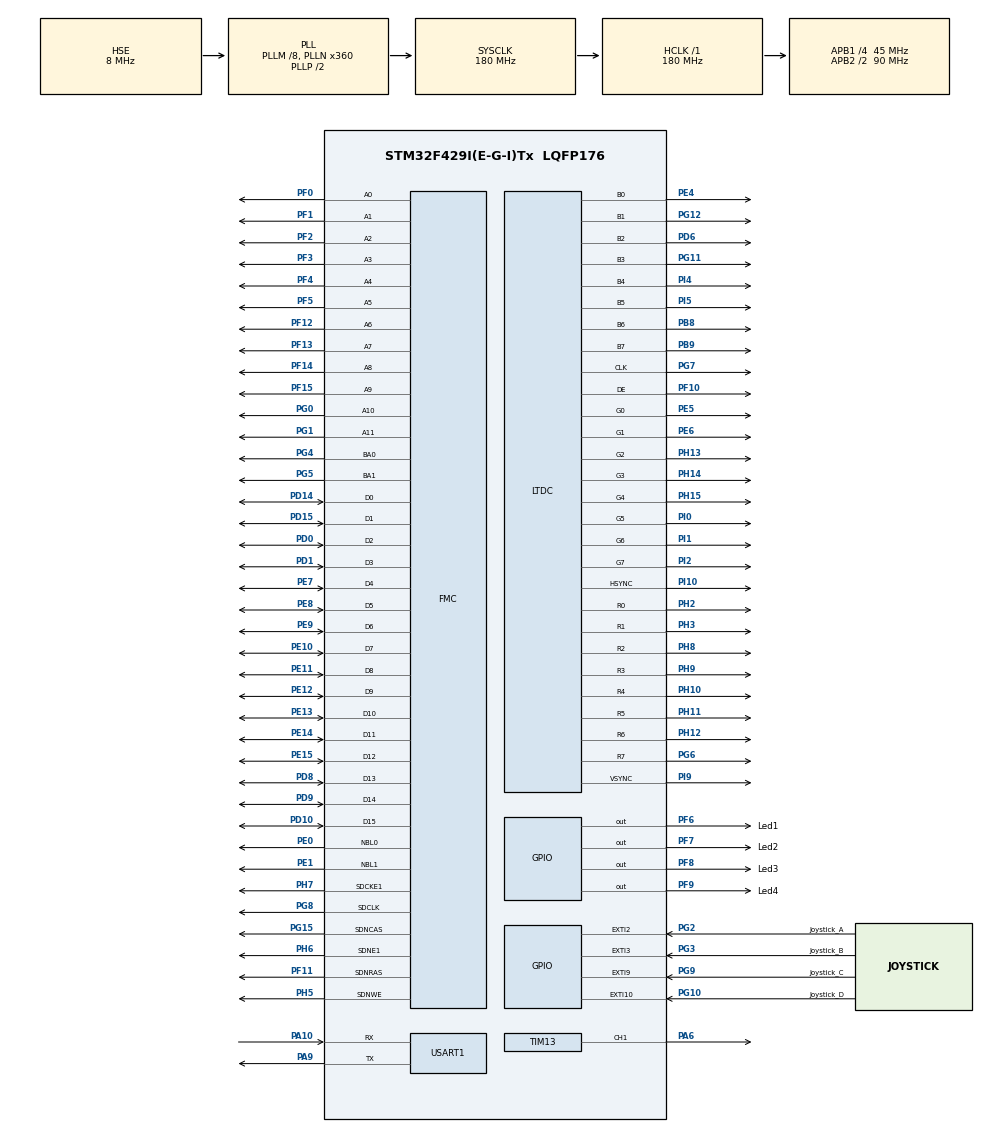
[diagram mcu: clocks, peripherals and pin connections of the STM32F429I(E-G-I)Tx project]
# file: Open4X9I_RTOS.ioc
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DMA2D.AlphaInvertedForeground=DMA2D_REGULAR_ALPHA
DMA2D.AlphaModeForeground=DMA2D_NO_MODIF_ALPHA
DMA2D.ColorMode=DMA2D_OUTPUT_ARGB8888
DMA2D.InputAlphaForeground=0
DMA2D.InputColorModeForeground=DMA2D_INPUT_A4
DMA2D.Mode=DMA2D_M2M_PFC
Dma.Request0=USART1_RX
Dma.Request1=USART1_TX
Dma.USART1_RX.0.Direction=DMA_PERIPH_TO_MEMORY
Dma.USART1_RX.0.FIFOMode=DMA_FIFOMODE_DISABLE
Dma.USART1_RX.0.Instance=DMA2_Stream2
Dma.USART1_RX.0.MemDataAlignment=DMA_MDATAALIGN_BYTE
Dma.USART1_RX.0.MemInc=DMA_MINC_ENABLE
Dma.USART1_RX.0.Mode=DMA_NORMAL
Dma.USART1_RX.0.PeriphDataAlignment=DMA_PDATAALIGN_BYTE
Dma.USART1_RX.0.PeriphInc=DMA_PINC_DISABLE
Dma.USART1_RX.0.Priority=DMA_PRIORITY_MEDIUM
Dma.USART1_TX.1.Direction=DMA_MEMORY_TO_PERIPH
Dma.USART1_TX.1.FIFOMode=DMA_FIFOMODE_DISABLE
Dma.USART1_TX.1.Instance=DMA2_Stream7
Dma.USART1_TX.1.MemDataAlignment=DMA_MDATAALIGN_BYTE
Dma.USART1_TX.1.MemInc=DMA_MINC_ENABLE
Dma.USART1_TX.1.Mode=DMA_NORMAL
Dma.USART1_TX.1.PeriphDataAlignment=DMA_PDATAALIGN_BYTE
Dma.USART1_TX.1.PeriphInc=DMA_PINC_DISABLE
Dma.USART1_TX.1.Priority=DMA_PRIORITY_MEDIUM
FMC.CASLatency2=FMC_SDRAM_CAS_LATENCY_3
FMC.ExitSelfRefreshDelay2=7
FMC.LoadToActiveDelay2=2
FMC.RCDDelay2=2
FMC.RPDelay1=2
FMC.RPDelay2=2
FMC.ReadBurst1=FMC_SDRAM_RBURST_ENABLE
FMC.ReadBurst2=FMC_SDRAM_RBURST_ENABLE
FMC.ReadPipeDelay1=FMC_SDRAM_RPIPE_DELAY_2
FMC.ReadPipeDelay2=FMC_SDRAM_RPIPE_DELAY_2
FMC.RowBitsNumber2=FMC_SDRAM_ROW_BITS_NUM_12
FMC.RowCycleDelay1=6
FMC.RowCycleDelay2=6
FMC.SDClockPeriod1=FMC_SDRAM_CLOCK_PERIOD_2
FMC.SDClockPeriod2=FMC_SDRAM_CLOCK_PERIOD_2
FMC.SelfRefreshTime2=4
FMC.WriteRecoveryTime2=2
FREERTOS.BinarySemaphores01=xRTCSemaphore,Dynamic,NULL;xDMA2DSemaphore,Dynamic,NULL;xBlinkCursorSemaphore,Dynamic,NULL;xLED1Semaphore,Dynamic,NULL;xLED2Semaphore,Dynamic,NULL;xLED3Semaphore,Dynamic,NULL;xLED4Semaphore,Dynamic,NULL;xInputMsgSemaphore,Dynamic,NULL;xCPULoadSemaphore,Dynamic,NULL;xDMA2Stream2Semaphore,Dynamic,NULL;xPS2CharSemaphore,Dynamic,NULL;xTIM6Semaphore,Dynamic,NULL;xTIM7Semaphore,Dynamic,NULL;xDMA2Stream7Semaphore,Dynamic,NULL
FREERTOS.CountingSemaphores01=xCAN_TXSemaphore,3,Dynamic,NULL
FREERTOS.Mutexes01=xCANStructPoint,Dynamic,NULL;xDMA2Stream2,Dynamic,NULL
FREERTOS.Queues01=QueuePrintLCD,16,sizeof LCDPrintTypeDef,NULL,Dynamic,NULL,NULL;QueueCANRecieve,10,sizeof CANRX_TypeDef,NULL,Dynamic,NULL,NULL;QueueCANTransmite,16,sizeof CANTX_TypeDef,NULL,Dynamic,NULL,NULL
FREERTOS.Tasks01=defaultTask,-3,128,StartDefaultTask,Default,NULL,Dynamic,NULL,NULL;LCDPrintCurrent,0,128,vLCDPrintCurrent,As external,NULL,Dynamic,NULL,NULL;PrintKernelLoad,0,128,vPrintKernelLoad,As external,NULL,Dynamic,NULL,NULL;PrintRTC,0,128,vPrintRTC,As external,NULL,Dynamic,NULL,NULL;LED1Blink,0,128,vLED1Blink,As external,NULL,Dynamic,NULL,NULL;LED2Blink,0,128,vLED2Blink,As external,NULL,Dynamic,NULL,NULL;LED3Blink,0,128,vLED3Blink,As external,NULL,Dynamic,NULL,NULL;LED4Blink,0,128,vLED4Blink,As external,NULL,Dynamic,NULL,NULL;CommandMsgDecod,0,128,vCommandMsgDecode,As external,NULL,Dynamic,NULL,NULL;LCDBlinkCursor,-2,128,vLCDBlinkCursor,As external,NULL,Dynamic,NULL,NULL;PS2CharDecode,0,128,vPS2CharDecode,As external,NULL,Dynamic,NULL,NULL
FREERTOS.configTIMER_QUEUE_LENGTH=5
FREERTOS.configTIMER_TASK_STACK_DEPTH=128
FREERTOS.configUSE_COUNTING_SEMAPHORES=1
FREERTOS.configUSE_IDLE_HOOK=1
FREERTOS.configUSE_TIMERS=0
LTDC.ActiveH=272
LTDC.ActiveW=480
LTDC.Alpha_L0=255
LTDC.Alpha_L1=255
LTDC.BlendingFactor1_L0=LTDC_BLENDING_FACTOR1_PAxCA
LTDC.BlendingFactor1_L1=LTDC_BLENDING_FACTOR1_PAxCA
LTDC.BlendingFactor2_L0=LTDC_BLENDING_FACTOR2_PAxCA
LTDC.BlendingFactor2_L1=LTDC_BLENDING_FACTOR2_PAxCA
LTDC.Blue_L0=150
LTDC.Blue_L1=150
LTDC.FBStartAdress_L0=0xD0000000
LTDC.FBStartAdress_L1=0xD00ff000
LTDC.Green_L1=100
LTDC.HBP=2
LTDC.HFP=2
LTDC.HSync=41
LTDC.ImageHeight_L0=240
LTDC.ImageHeight_L1=272
LTDC.ImageWidth_L0=480
LTDC.ImageWidth_L1=480
LTDC.Layers=1
LTDC.PixelFormat_L0=LTDC_PIXEL_FORMAT_ARGB8888
LTDC.Red_L0=100
LTDC.VSync=10
LTDC.WindowX0_L0=0
LTDC.WindowX0_L1=0
LTDC.WindowX1_L0=480
LTDC.WindowX1_L1=480
LTDC.WindowY0_L0=0
LTDC.WindowY0_L1=0
LTDC.WindowY1_L0=240
LTDC.WindowY1_L1=272
Mcu.Family=STM32F4
Mcu.Name=STM32F429I(E-G-I)Tx
Mcu.Package=LQFP176
Mcu.UserConstants=constant,0x10;SDRAM_BASE,0xD0000000;SDRAM_SIZE,0x800000;BLUE,0x000000FF;GREEN,0x0000FF00;RED,0x00FF0000;CYAN,0x0000FFFF;MAGENTA,0x00FF00FF;YELLOW,0x00FFFF00;WHITE,0x00FFFFFF;CURSOR_WIDTH,8;CURSOR_HEIGHT,3;LAYER_0,0;LAYER_1,1;BLACK,0x00000000
NVIC.DMA2D_IRQn=true\:6\:0\:true\:false\:true\:true
NVIC.DMA2_Stream2_IRQn=true\:5\:0\:false\:false\:true\:true
NVIC.DMA2_Stream7_IRQn=true\:5\:0\:false\:false\:true\:true
NVIC.EXTI15_10_IRQn=true\:10\:0\:true\:false\:true\:true
NVIC.EXTI2_IRQn=true\:10\:0\:true\:false\:true\:true
NVIC.EXTI3_IRQn=true\:10\:0\:true\:false\:true\:true
NVIC.EXTI9_5_IRQn=true\:10\:0\:true\:false\:true\:true
NVIC.LTDC_IRQn=true\:5\:0\:false\:false\:true\:true
NVIC.PriorityGroup=NVIC_PRIORITYGROUP_4
NVIC.RTC_WKUP_IRQn=true\:7\:0\:true\:false\:true\:true
NVIC.TIM6_DAC_IRQn=true\:8\:0\:true\:false\:true\:true
NVIC.TIM7_IRQn=true\:8\:0\:true\:false\:true\:true
NVIC.TIM8_TRG_COM_TIM14_IRQn=true\:0\:0\:false\:false\:true\:false
NVIC.TimeBase=TIM8_TRG_COM_TIM14_IRQn
NVIC.TimeBaseIP=TIM14
NVIC.USART1_IRQn=true\:7\:0\:true\:false\:true\:true
PA10.GPIO_Speed=GPIO_SPEED_FREQ_LOW
PA10.Mode=Asynchronous
PA10.Signal=USART1_RX
PA13.Mode=Serial_Wire
PA13.Signal=SYS_JTMS-SWDIO
PA14.Mode=Serial_Wire
PA14.Signal=SYS_JTCK-SWCLK
PA6.Signal=S_TIM13_CH1
PA9.GPIO_Speed=GPIO_SPEED_FREQ_LOW
PA9.Mode=Asynchronous
PA9.Signal=USART1_TX
PB8.GPIO_Mode=GPIO_MODE_AF_PP
PB8.GPIO_PuPd=GPIO_NOPULL
PB8.GPIO_Speed=GPIO_SPEED_FREQ_HIGH
PB8.Mode=RGB888
PB8.Signal=LTDC_B6
PB9.GPIO_Mode=GPIO_MODE_AF_PP
PB9.GPIO_PuPd=GPIO_NOPULL
PB9.GPIO_Speed=GPIO_SPEED_FREQ_HIGH
PB9.Mode=RGB888
PB9.Signal=LTDC_B7
PC14/OSC32_IN.Mode=LSE-External-Oscillator
PC14/OSC32_IN.Signal=RCC_OSC32_IN
PC15/OSC32_OUT.Mode=LSE-External-Oscillator
PC15/OSC32_OUT.Signal=RCC_OSC32_OUT
PD0.Signal=FMC_D2_DA2
PD1.Signal=FMC_D3_DA3
PD10.Signal=FMC_D15_DA15
PD14.Signal=FMC_D0_DA0
PD15.Signal=FMC_D1_DA1
PD6.GPIO_Mode=GPIO_MODE_AF_PP
PD6.GPIO_PuPd=GPIO_NOPULL
PD6.GPIO_Speed=GPIO_SPEED_FREQ_HIGH
PD6.Mode=RGB888
PD6.Signal=LTDC_B2
PD8.Signal=FMC_D13_DA13
PD9.Signal=FMC_D14_DA14
PE0.Signal=FMC_NBL0
PE1.Signal=FMC_NBL1
PE10.Signal=FMC_D7_DA7
PE11.Signal=FMC_D8_DA8
PE12.Signal=FMC_D9_DA9
PE13.Signal=FMC_D10_DA10
PE14.Signal=FMC_D11_DA11
PE15.Signal=FMC_D12_DA12
PE4.GPIO_Mode=GPIO_MODE_AF_PP
PE4.GPIO_PuPd=GPIO_NOPULL
PE4.GPIO_Speed=GPIO_SPEED_FREQ_HIGH
PE4.Mode=RGB888
PE4.Signal=LTDC_B0
PE5.GPIO_Mode=GPIO_MODE_AF_PP
PE5.GPIO_PuPd=GPIO_NOPULL
PE5.GPIO_Speed=GPIO_SPEED_FREQ_HIGH
PE5.Mode=RGB888
PE5.Signal=LTDC_G0
PE6.GPIO_Mode=GPIO_MODE_AF_PP
PE6.GPIO_PuPd=GPIO_NOPULL
PE6.GPIO_Speed=GPIO_SPEED_FREQ_HIGH
PE6.Mode=RGB888
PE6.Signal=LTDC_G1
PE7.Signal=FMC_D4_DA4
PE8.Signal=FMC_D5_DA5
PE9.Signal=FMC_D6_DA6
PF0.Signal=FMC_A0
PF1.Signal=FMC_A1
PF10.GPIO_Mode=GPIO_MODE_AF_PP
PF10.GPIO_PuPd=GPIO_NOPULL
PF10.GPIO_Speed=GPIO_SPEED_FREQ_HIGH
PF10.Mode=RGB888
PF10.Signal=LTDC_DE
PF11.Signal=FMC_SDNRAS
PF12.Signal=FMC_A6
PF13.Signal=FMC_A7
PF14.Signal=FMC_A8
PF15.Signal=FMC_A9
PF2.Signal=FMC_A2
PF3.Signal=FMC_A3
PF4.Signal=FMC_A4
PF5.Signal=FMC_A5
PF6.GPIO_Label=Led1
PF6.Signal=GPIO_Output
PF7.GPIO_Label=Led2
PF7.Signal=GPIO_Output
PF8.GPIO_Label=Led3
PF8.Signal=GPIO_Output
PF9.GPIO_Label=Led4
PF9.Signal=GPIO_Output
PG0.Signal=FMC_A10
PG1.Signal=FMC_A11
PG10.GPIO_Label=Joystick_D
PG10.GPIO_ModeDefaultEXTI=GPIO_MODE_IT_FALLING
PG10.GPIO_PuPd=GPIO_PULLUP
PG10.Signal=GPXTI10
PG11.GPIO_Mode=GPIO_MODE_AF_PP
PG11.GPIO_PuPd=GPIO_NOPULL
PG11.GPIO_Speed=GPIO_SPEED_FREQ_HIGH
PG11.Mode=RGB888
PG11.Signal=LTDC_B3
PG12.GPIO_Mode=GPIO_MODE_AF_PP
PG12.GPIO_PuPd=GPIO_NOPULL
PG12.GPIO_Speed=GPIO_SPEED_FREQ_HIGH
PG12.Mode=RGB888
PG12.Signal=LTDC_B1
PG15.Signal=FMC_SDNCAS
PG2.GPIO_Label=Joystick_A
PG2.GPIO_ModeDefaultEXTI=GPIO_MODE_IT_FALLING
PG2.GPIO_PuPd=GPIO_PULLUP
PG2.Signal=GPXTI2
PG3.GPIO_Label=Joystick_B
PG3.GPIO_ModeDefaultEXTI=GPIO_MODE_IT_FALLING
PG3.GPIO_PuPd=GPIO_PULLUP
PG3.Signal=GPXTI3
PG4.Signal=FMC_A14_BA0
PG5.Signal=FMC_A15_BA1
PG6.GPIO_Mode=GPIO_MODE_AF_PP
PG6.GPIO_PuPd=GPIO_NOPULL
PG6.GPIO_Speed=GPIO_SPEED_FREQ_HIGH
PG6.Mode=RGB888
PG6.Signal=LTDC_R7
PG7.GPIO_Mode=GPIO_MODE_AF_PP
PG7.GPIO_PuPd=GPIO_NOPULL
PG7.GPIO_Speed=GPIO_SPEED_FREQ_HIGH
PG7.Mode=RGB888
PG7.Signal=LTDC_CLK
PG8.Signal=FMC_SDCLK
PG9.GPIO_Label=Joystick_C
PG9.GPIO_ModeDefaultEXTI=GPIO_MODE_IT_FALLING
PG9.GPIO_PuPd=GPIO_PULLUP
PG9.Signal=GPXTI9
PH0/OSC_IN.Mode=HSE-External-Oscillator
PH0/OSC_IN.Signal=RCC_OSC_IN
PH1/OSC_OUT.Mode=HSE-External-Oscillator
PH1/OSC_OUT.Signal=RCC_OSC_OUT
PH10.GPIO_Mode=GPIO_MODE_AF_PP
PH10.GPIO_PuPd=GPIO_NOPULL
PH10.GPIO_Speed=GPIO_SPEED_FREQ_HIGH
PH10.Mode=RGB888
PH10.Signal=LTDC_R4
PH11.GPIO_Mode=GPIO_MODE_AF_PP
PH11.GPIO_PuPd=GPIO_NOPULL
PH11.GPIO_Speed=GPIO_SPEED_FREQ_HIGH
PH11.Mode=RGB888
PH11.Signal=LTDC_R5
PH12.GPIO_Mode=GPIO_MODE_AF_PP
PH12.GPIO_PuPd=GPIO_NOPULL
PH12.GPIO_Speed=GPIO_SPEED_FREQ_HIGH
PH12.Mode=RGB888
PH12.Signal=LTDC_R6
PH13.GPIO_Mode=GPIO_MODE_AF_PP
PH13.GPIO_PuPd=GPIO_NOPULL
PH13.GPIO_Speed=GPIO_SPEED_FREQ_HIGH
PH13.Mode=RGB888
PH13.Signal=LTDC_G2
PH14.GPIO_Mode=GPIO_MODE_AF_PP
PH14.GPIO_PuPd=GPIO_NOPULL
PH14.GPIO_Speed=GPIO_SPEED_FREQ_HIGH
PH14.Mode=RGB888
PH14.Signal=LTDC_G3
PH15.GPIO_Mode=GPIO_MODE_AF_PP
PH15.GPIO_PuPd=GPIO_NOPULL
PH15.GPIO_Speed=GPIO_SPEED_FREQ_HIGH
PH15.Mode=RGB888
PH15.Signal=LTDC_G4
PH2.GPIO_Mode=GPIO_MODE_AF_PP
PH2.GPIO_PuPd=GPIO_NOPULL
PH2.GPIO_Speed=GPIO_SPEED_FREQ_HIGH
PH2.Mode=RGB888
PH2.Signal=LTDC_R0
PH3.GPIO_Mode=GPIO_MODE_AF_PP
PH3.GPIO_PuPd=GPIO_NOPULL
PH3.GPIO_Speed=GPIO_SPEED_FREQ_HIGH
PH3.Mode=RGB888
PH3.Signal=LTDC_R1
PH5.GPIO_Mode=GPIO_MODE_AF_PP
PH5.GPIO_PuPd=GPIO_NOPULL
PH5.GPIO_Speed=GPIO_SPEED_FREQ_VERY_HIGH
PH5.GPIO_Speed_High_Default=GPIO_SPEED_FREQ_VERY_HIGH
PH5.Signal=FMC_SDNWE
PH6.Mode=SdramChipSelect2_2
PH6.Signal=FMC_SDNE1
PH7.Mode=SdramChipSelect2_2
PH7.Signal=FMC_SDCKE1
PH8.GPIO_Mode=GPIO_MODE_AF_PP
PH8.GPIO_PuPd=GPIO_NOPULL
PH8.GPIO_Speed=GPIO_SPEED_FREQ_HIGH
PH8.Mode=RGB888
PH8.Signal=LTDC_R2
PH9.GPIO_Mode=GPIO_MODE_AF_PP
PH9.GPIO_PuPd=GPIO_NOPULL
PH9.GPIO_Speed=GPIO_SPEED_FREQ_HIGH
PH9.Mode=RGB888
PH9.Signal=LTDC_R3
PI0.GPIO_Mode=GPIO_MODE_AF_PP
PI0.GPIO_PuPd=GPIO_NOPULL
PI0.GPIO_Speed=GPIO_SPEED_FREQ_HIGH
PI0.Mode=RGB888
PI0.Signal=LTDC_G5
PI1.GPIO_Mode=GPIO_MODE_AF_PP
PI1.GPIO_PuPd=GPIO_NOPULL
PI1.GPIO_Speed=GPIO_SPEED_FREQ_HIGH
PI1.Mode=RGB888
PI1.Signal=LTDC_G6
PI10.GPIO_Mode=GPIO_MODE_AF_PP
PI10.GPIO_PuPd=GPIO_NOPULL
PI10.GPIO_Speed=GPIO_SPEED_FREQ_HIGH
PI10.Mode=RGB888
PI10.Signal=LTDC_HSYNC
PI2.GPIO_Mode=GPIO_MODE_AF_PP
PI2.GPIO_PuPd=GPIO_NOPULL
PI2.GPIO_Speed=GPIO_SPEED_FREQ_HIGH
PI2.Mode=RGB888
PI2.Signal=LTDC_G7
PI4.GPIO_Mode=GPIO_MODE_AF_PP
PI4.GPIO_PuPd=GPIO_NOPULL
PI4.GPIO_Speed=GPIO_SPEED_FREQ_HIGH
PI4.Mode=RGB888
PI4.Signal=LTDC_B4
PI5.GPIO_Mode=GPIO_MODE_AF_PP
PI5.GPIO_PuPd=GPIO_NOPULL
PI5.GPIO_Speed=GPIO_SPEED_FREQ_HIGH
PI5.Mode=RGB888
PI5.Signal=LTDC_B5
PI9.GPIO_Mode=GPIO_MODE_AF_PP
PI9.GPIO_PuPd=GPIO_NOPULL
PI9.GPIO_Speed=GPIO_SPEED_FREQ_HIGH
PI9.Mode=RGB888
PI9.Signal=LTDC_VSYNC
ProjectManager.HeapSize=0x200
ProjectManager.StackSize=0x400
ProjectManager.TargetToolchain=MDK-ARM V5
RCC.48MHZClocksFreq_Value=45000000
RCC.AHBFreq_Value=180000000
RCC.APB1CLKDivider=RCC_HCLK_DIV4
RCC.APB1Freq_Value=45000000
RCC.APB1TimFreq_Value=90000000
RCC.APB2CLKDivider=RCC_HCLK_DIV2
RCC.APB2Freq_Value=90000000
RCC.APB2TimFreq_Value=180000000
RCC.CortexFreq_Value=180000000
RCC.HCLKFreq_Value=180000000
RCC.HSE_VALUE=8000000
RCC.HSI_VALUE=16000000
RCC.PLLM=8
RCC.PLLN=360
RCC.PLLQ=8
RCC.PLLSAIDivR=RCC_PLLSAIDIVR_16
RCC.PLLSAIN=288
RCC.PLLSourceVirtual=RCC_PLLSOURCE_HSE
RCC.RCC_RTC_Clock_Source=RCC_RTCCLKSOURCE_LSE
RCC.RCC_RTC_Clock_SourceVirtual=RCC_RTCCLKSOURCE_LSE
RCC.SYSCLKFreq_VALUE=180000000
RCC.SYSCLKSource=RCC_SYSCLKSOURCE_PLLCLK
RCC.VCOOutputFreq_Value=360000000
RTC.Date=17
RTC.DayLightSaving=RTC_DAYLIGHTSAVING_NONE
RTC.Hours=12
RTC.Month=RTC_MONTH_AUGUST
RTC.WakeUpClock=RTC_WAKEUPCLOCK_CK_SPRE_16BITS
RTC.WakeUpCounter=0
RTC.WeekDay=RTC_WEEKDAY_FRIDAY
RTC.Year=17
SH.FMC_A0.0=FMC_A0,12b-sda2
SH.FMC_A1.0=FMC_A1,12b-sda2
SH.FMC_A10.0=FMC_A10,12b-sda2
SH.FMC_A11.0=FMC_A11,12b-sda2
SH.FMC_A14_BA0.0=FMC_BA0,FourSdramBanks2
SH.FMC_A15_BA1.0=FMC_BA1,FourSdramBanks2
SH.FMC_A2.0=FMC_A2,12b-sda2
SH.FMC_A3.0=FMC_A3,12b-sda2
SH.FMC_A4.0=FMC_A4,12b-sda2
SH.FMC_A5.0=FMC_A5,12b-sda2
SH.FMC_A6.0=FMC_A6,12b-sda2
SH.FMC_A7.0=FMC_A7,12b-sda2
SH.FMC_A8.0=FMC_A8,12b-sda2
SH.FMC_A9.0=FMC_A9,12b-sda2
SH.FMC_D0_DA0.0=FMC_D0,sd-16b-d2
SH.FMC_D10_DA10.0=FMC_D10,sd-16b-d2
SH.FMC_D11_DA11.0=FMC_D11,sd-16b-d2
SH.FMC_D12_DA12.0=FMC_D12,sd-16b-d2
SH.FMC_D13_DA13.0=FMC_D13,sd-16b-d2
SH.FMC_D14_DA14.0=FMC_D14,sd-16b-d2
SH.FMC_D15_DA15.0=FMC_D15,sd-16b-d2
SH.FMC_D1_DA1.0=FMC_D1,sd-16b-d2
SH.FMC_D2_DA2.0=FMC_D2,sd-16b-d2
SH.FMC_D3_DA3.0=FMC_D3,sd-16b-d2
SH.FMC_D4_DA4.0=FMC_D4,sd-16b-d2
SH.FMC_D5_DA5.0=FMC_D5,sd-16b-d2
SH.FMC_D6_DA6.0=FMC_D6,sd-16b-d2
SH.FMC_D7_DA7.0=FMC_D7,sd-16b-d2
SH.FMC_D8_DA8.0=FMC_D8,sd-16b-d2
SH.FMC_D9_DA9.0=FMC_D9,sd-16b-d2
SH.FMC_NBL0.0=FMC_NBL0,Sd2ByteEnable2
SH.FMC_NBL1.0=FMC_NBL1,Sd2ByteEnable2
SH.FMC_SDCLK.0=FMC_SDCLK,12b-sda2
SH.FMC_SDNCAS.0=FMC_SDNCAS,12b-sda2
SH.FMC_SDNRAS.0=FMC_SDNRAS,12b-sda2
SH.FMC_SDNWE.0=FMC_SDNWE,12b-sda2
SH.S_TIM13_CH1.0=TIM13_CH1,PWM Generation1 CH1
TIM13.Channel=TIM_CHANNEL_1
TIM13.OCMode_PWM=TIM_OCMODE_PWM2
TIM13.OCPolarity_1=TIM_OCPOLARITY_LOW
TIM13.Period=200
TIM13.Prescaler=4499
TIM13.Pulse=70
TIM6.Period=4000
TIM6.Prescaler=44999
TIM7.Period=2000
TIM7.Prescaler=44999
USART1.VirtualMode=VM_ASYNC
VP_CRC_VS_CRC.Mode=CRC_Activate
VP_DMA2D_VS_DMA2D.Mode=DMA2D_Activate
VP_FREERTOS_VS_ENABLE.Mode=Enabled
VP_RTC_VS_RTC_Activate.Mode=RTC_Enabled
VP_RTC_VS_RTC_Calendar.Mode=RTC_Calendar
VP_RTC_VS_RTC_WakeUp_intern.Mode=WakeUp
VP_SYS_VS_tim14.Mode=TIM14
VP_TIM13_VS_ClockSourceINT.Mode=Enable_Timer
VP_TIM6_VS_ClockSourceINT.Mode=Enable_Timer
VP_TIM7_VS_ClockSourceINT.Mode=Enable_Timer
board=Open4X9I_RTOS

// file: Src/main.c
/**
  ******************************************************************************
  * File Name          : main.c
  * Description        : Main program body
  ******************************************************************************
  * This notice applies to any and all portions of this file
  * that are not between comment pairs USER CODE BEGIN and
  * USER CODE END. Other portions of this file, whether
  * inserted by the user or by software development tools
  * are owned by their respective copyright owners.
  *
  * Copyright (c) 2017 STMicroelectronics International N.V.
  * All rights reserved.
  *
  * Redistribution and use in source and binary forms, with or without
  * modification, are permitted, provided that the following conditions are met:
  *
  * 1. Redistribution of source code must retain the above copyright notice,
  *    this list of conditions and the following disclaimer.
  * 2. Redistributions in binary form must reproduce the above copyright notice,
  *    this list of conditions and the following disclaimer in the documentation
  *    and/or other materials provided with the distribution.
  * 3. Neither the name of STMicroelectronics nor the names of other
  *    contributors to this software may be used to endorse or promote products
  *    derived from this software without specific written permission.
  * 4. This software, including modifications and/or derivative works of this
  *    software, must execute solely and exclusively on microcontroller or
  *    microprocessor devices manufactured by or for STMicroelectronics.
  * 5. Redistribution and use of this software other than as permitted under
  *    this license is void and will automatically terminate your rights under
  *    this license.
  *
  * THIS SOFTWARE IS PROVIDED BY STMICROELECTRONICS AND CONTRIBUTORS "AS IS"
  * AND ANY EXPRESS, IMPLIED OR STATUTORY WARRANTIES, INCLUDING, BUT NOT
  * LIMITED TO, THE IMPLIED WARRANTIES OF MERCHANTABILITY, FITNESS FOR A
  * PARTICULAR PURPOSE AND NON-INFRINGEMENT OF THIRD PARTY INTELLECTUAL PROPERTY
  * RIGHTS ARE DISCLAIMED TO THE FULLEST EXTENT PERMITTED BY LAW. IN NO EVENT
  * SHALL STMICROELECTRONICS OR CONTRIBUTORS BE LIABLE FOR ANY DIRECT, INDIRECT,
  * INCIDENTAL, SPECIAL, EXEMPLARY, OR CONSEQUENTIAL DAMAGES (INCLUDING, BUT NOT
  * LIMITED TO, PROCUREMENT OF SUBSTITUTE GOODS OR SERVICES; LOSS OF USE, DATA,
  * OR PROFITS; OR BUSINESS INTERRUPTION) HOWEVER CAUSED AND ON ANY THEORY OF
  * LIABILITY, WHETHER IN CONTRACT, STRICT LIABILITY, OR TORT (INCLUDING
  * NEGLIGENCE OR OTHERWISE) ARISING IN ANY WAY OUT OF THE USE OF THIS SOFTWARE,
  * EVEN IF ADVISED OF THE POSSIBILITY OF SUCH DAMAGE.
  *
  ******************************************************************************
  */
#include "main.h"
#include "stm32f4xx_hal.h"
#include "cmsis_os.h"

/* USER CODE BEGIN Includes */
#include "mytask.h"
#include "LCDdriver.h"
#include "PS2_Keyboard.h"
#include "CAN.h"

#define REFRESH_COUNT           ((uint32_t)1386)   /* SDRAM refresh counter */
#define SDRAM_TIMEOUT           ((uint32_t)0xFFFF)
/* USER CODE END Includes */

CRC_HandleTypeDef hcrc;

DMA2D_HandleTypeDef hdma2d;

LTDC_HandleTypeDef hltdc;

RTC_HandleTypeDef hrtc;

TIM_HandleTypeDef htim6;
TIM_HandleTypeDef htim7;
TIM_HandleTypeDef htim13;

UART_HandleTypeDef huart1;
DMA_HandleTypeDef hdma_usart1_rx;
DMA_HandleTypeDef hdma_usart1_tx;

SDRAM_HandleTypeDef hsdram2;

osThreadId defaultTaskHandle;
osThreadId LCDPrintCurrentHandle;
osThreadId PrintKernelLoadHandle;
osThreadId PrintRTCHandle;
osThreadId LED1BlinkHandle;
osThreadId LED2BlinkHandle;
osThreadId LED3BlinkHandle;
osThreadId LED4BlinkHandle;
osThreadId CommandMsgDecodHandle;
osThreadId LCDBlinkCursorHandle;
osThreadId PS2CharDecodeHandle;
osMessageQId QueuePrintLCDHandle;
osMessageQId QueueCANRecieveHandle;
osMessageQId QueueCANTransmiteHandle;
osMutexId xCANStructPointHandle;
osMutexId xDMA2Stream2Handle;
osSemaphoreId xRTCSemaphoreHandle;
osSemaphoreId xDMA2DSemaphoreHandle;
osSemaphoreId xBlinkCursorSemaphoreHandle;
osSemaphoreId xLED1SemaphoreHandle;
osSemaphoreId xLED2SemaphoreHandle;
osSemaphoreId xLED3SemaphoreHandle;
osSemaphoreId xLED4SemaphoreHandle;
osSemaphoreId xInputMsgSemaphoreHandle;
osSemaphoreId xCPULoadSemaphoreHandle;
osSemaphoreId xDMA2Stream2SemaphoreHandle;
osSemaphoreId xPS2CharSemaphoreHandle;
osSemaphoreId xTIM6SemaphoreHandle;
osSemaphoreId xTIM7SemaphoreHandle;
osSemaphoreId xDMA2Stream7SemaphoreHandle;
osSemaphoreId xCAN_TXSemaphoreHandle;

/* USER CODE BEGIN PV */
/* Private variables ---------------------------------------------------------*/

xQueueHandle xQueueCANTX,xQueueCANRX;
//sThreadId TaskHandle1,TaskHandle2;
/* USER CODE END PV */

void SystemClock_Config(void);
static void MX_GPIO_Init(void);
static void MX_DMA_Init(void);
static void MX_CRC_Init(void);
static void MX_DMA2D_Init(void);
static void MX_FMC_Init(void);
static void MX_LTDC_Init(void);
static void MX_RTC_Init(void);
static void MX_TIM6_Init(void);
static void MX_TIM7_Init(void);
static void MX_TIM13_Init(void);
static void MX_USART1_UART_Init(void);
void StartDefaultTask(void const * argument);
extern void vLCDPrintCurrent(void const * argument);
extern void vPrintKernelLoad(void const * argument);
extern void vPrintRTC(void const * argument);
extern void vLED1Blink(void const * argument);
extern void vLED2Blink(void const * argument);
extern void vLED3Blink(void const * argument);
extern void vLED4Blink(void const * argument);
extern void vCommandMsgDecode(void const * argument);
extern void vLCDBlinkCursor(void const * argument);
extern void vPS2CharDecode(void const * argument);

void HAL_TIM_MspPostInit(TIM_HandleTypeDef *htim);

/* USER CODE BEGIN PFP */
/* Private function prototypes -----------------------------------------------*/

void SDRAM_Initialization_sequence(uint32_t RefreshCount);

/* USER CODE END PFP */

int main(void)
{

  /* MCU Configuration----------------------------------------------------------*/

  /* Reset of all peripherals, Initializes the Flash interface and the Systick. */
  HAL_Init();

  /* Configure the system clock */
  SystemClock_Config();

  /* Initialize all configured peripherals */
  MX_GPIO_Init();
  MX_DMA_Init();
  MX_CRC_Init();
  MX_DMA2D_Init();
  MX_FMC_Init();
  MX_LTDC_Init();
  MX_RTC_Init();
  MX_TIM6_Init();
  MX_TIM7_Init();
  MX_TIM13_Init();
  MX_USART1_UART_Init();

  /* USER CODE BEGIN 2 */
		SDRAM_Initialization_sequence(REFRESH_COUNT);
		HAL_RTCEx_EnableBypassShadow(&hrtc);

  /* USER CODE END 2 */

  /* Create the mutex(es) */
  /* definition and creation of xCANStructPoint */
  osMutexDef(xCANStructPoint);
  xCANStructPointHandle = osMutexCreate(osMutex(xCANStructPoint));

  /* definition and creation of xDMA2Stream2 */
  osMutexDef(xDMA2Stream2);
  xDMA2Stream2Handle = osMutexCreate(osMutex(xDMA2Stream2));

  /* Create the semaphores(s) */
  /* definition and creation of xRTCSemaphore */
  osSemaphoreDef(xRTCSemaphore);
  xRTCSemaphoreHandle = osSemaphoreCreate(osSemaphore(xRTCSemaphore), 1);

  /* definition and creation of xDMA2DSemaphore */
  osSemaphoreDef(xDMA2DSemaphore);
  xDMA2DSemaphoreHandle = osSemaphoreCreate(osSemaphore(xDMA2DSemaphore), 1);

  /* definition and creation of xBlinkCursorSemaphore */
  osSemaphoreDef(xBlinkCursorSemaphore);
  xBlinkCursorSemaphoreHandle = osSemaphoreCreate(osSemaphore(xBlinkCursorSemaphore), 1);

  /* definition and creation of xLED1Semaphore */
  osSemaphoreDef(xLED1Semaphore);
  xLED1SemaphoreHandle = osSemaphoreCreate(osSemaphore(xLED1Semaphore), 1);

  /* definition and creation of xLED2Semaphore */
  osSemaphoreDef(xLED2Semaphore);
  xLED2SemaphoreHandle = osSemaphoreCreate(osSemaphore(xLED2Semaphore), 1);

  /* definition and creation of xLED3Semaphore */
  osSemaphoreDef(xLED3Semaphore);
  xLED3SemaphoreHandle = osSemaphoreCreate(osSemaphore(xLED3Semaphore), 1);

  /* definition and creation of xLED4Semaphore */
  osSemaphoreDef(xLED4Semaphore);
  xLED4SemaphoreHandle = osSemaphoreCreate(osSemaphore(xLED4Semaphore), 1);

  /* definition and creation of xInputMsgSemaphore */
  osSemaphoreDef(xInputMsgSemaphore);
  xInputMsgSemaphoreHandle = osSemaphoreCreate(osSemaphore(xInputMsgSemaphore), 1);

  /* definition and creation of xCPULoadSemaphore */
  osSemaphoreDef(xCPULoadSemaphore);
  xCPULoadSemaphoreHandle = osSemaphoreCreate(osSemaphore(xCPULoadSemaphore), 1);

  /* definition and creation of xDMA2Stream2Semaphore */
  osSemaphoreDef(xDMA2Stream2Semaphore);
  xDMA2Stream2SemaphoreHandle = osSemaphoreCreate(osSemaphore(xDMA2Stream2Semaphore), 1);

  /* definition and creation of xPS2CharSemaphore */
  osSemaphoreDef(xPS2CharSemaphore);
  xPS2CharSemaphoreHandle = osSemaphoreCreate(osSemaphore(xPS2CharSemaphore), 1);

  /* definition and creation of xTIM6Semaphore */
  osSemaphoreDef(xTIM6Semaphore);
  xTIM6SemaphoreHandle = osSemaphoreCreate(osSemaphore(xTIM6Semaphore), 1);

  /* definition and creation of xTIM7Semaphore */
  osSemaphoreDef(xTIM7Semaphore);
  xTIM7SemaphoreHandle = osSemaphoreCreate(osSemaphore(xTIM7Semaphore), 1);

  /* definition and creation of xDMA2Stream7Semaphore */
  osSemaphoreDef(xDMA2Stream7Semaphore);
  xDMA2Stream7SemaphoreHandle = osSemaphoreCreate(osSemaphore(xDMA2Stream7Semaphore), 1);

  /* definition and creation of xCAN_TXSemaphore */
  osSemaphoreDef(xCAN_TXSemaphore);
  xCAN_TXSemaphoreHandle = osSemaphoreCreate(osSemaphore(xCAN_TXSemaphore), 1);

  /* Create the thread(s) */
  /* definition and creation of defaultTask */
  osThreadDef(defaultTask, StartDefaultTask, osPriorityIdle, 0, 128);
  defaultTaskHandle = osThreadCreate(osThread(defaultTask), NULL);

  /* definition and creation of LCDPrintCurrent */
  osThreadDef(LCDPrintCurrent, vLCDPrintCurrent, osPriorityNormal, 0, 128);
  LCDPrintCurrentHandle = osThreadCreate(osThread(LCDPrintCurrent), NULL);

  /* definition and creation of PrintKernelLoad */
  osThreadDef(PrintKernelLoad, vPrintKernelLoad, osPriorityNormal, 0, 128);
  PrintKernelLoadHandle = osThreadCreate(osThread(PrintKernelLoad), NULL);

  /* definition and creation of PrintRTC */
  osThreadDef(PrintRTC, vPrintRTC, osPriorityNormal, 0, 128);
  PrintRTCHandle = osThreadCreate(osThread(PrintRTC), NULL);

  /* definition and creation of LED1Blink */
  osThreadDef(LED1Blink, vLED1Blink, osPriorityNormal, 0, 128);
  LED1BlinkHandle = osThreadCreate(osThread(LED1Blink), NULL);

  /* definition and creation of LED2Blink */
  osThreadDef(LED2Blink, vLED2Blink, osPriorityNormal, 0, 128);
  LED2BlinkHandle = osThreadCreate(osThread(LED2Blink), NULL);

  /* definition and creation of LED3Blink */
  osThreadDef(LED3Blink, vLED3Blink, osPriorityNormal, 0, 128);
  LED3BlinkHandle = osThreadCreate(osThread(LED3Blink), NULL);

  /* definition and creation of LED4Blink */
  osThreadDef(LED4Blink, vLED4Blink, osPriorityNormal, 0, 128);
  LED4BlinkHandle = osThreadCreate(osThread(LED4Blink), NULL);

  /* definition and creation of CommandMsgDecod */
  osThreadDef(CommandMsgDecod, vCommandMsgDecode, osPriorityNormal, 0, 128);
  CommandMsgDecodHandle = osThreadCreate(osThread(CommandMsgDecod), NULL);

  /* definition and creation of LCDBlinkCursor */
  osThreadDef(LCDBlinkCursor, vLCDBlinkCursor, osPriorityLow, 0, 128);
  LCDBlinkCursorHandle = osThreadCreate(osThread(LCDBlinkCursor), NULL);

  /* definition and creation of PS2CharDecode */
  osThreadDef(PS2CharDecode, vPS2CharDecode, osPriorityNormal, 0, 128);
  PS2CharDecodeHandle = osThreadCreate(osThread(PS2CharDecode), NULL);

  /* USER CODE BEGIN RTOS_THREADS */
  /* add threads, ... */

	osThreadSuspend (LCDPrintCurrentHandle);
	osThreadSuspend (PrintKernelLoadHandle);
	osThreadSuspend (PrintRTCHandle);
	osThreadSuspend (LED1BlinkHandle);
	osThreadSuspend (LED2BlinkHandle);
	osThreadSuspend (LED3BlinkHandle);
	osThreadSuspend (LED4BlinkHandle);
	osThreadSuspend(CommandMsgDecodHandle);
	osThreadSuspend(LCDBlinkCursorHandle);
	osThreadSuspend(PS2CharDecodeHandle);

	osSemaphoreWait(xLED1SemaphoreHandle,osWaitForever);
	osSemaphoreWait(xLED2SemaphoreHandle,osWaitForever);
	osSemaphoreWait(xLED3SemaphoreHandle,osWaitForever);
	osSemaphoreWait(xLED4SemaphoreHandle,osWaitForever);
	osSemaphoreWait(xDMA2Stream2SemaphoreHandle,osWaitForever);
	osSemaphoreWait(xInputMsgSemaphoreHandle,osWaitForever);
	osSemaphoreWait(xPS2CharSemaphoreHandle,osWaitForever);
	osSemaphoreWait(xTIM6SemaphoreHandle,osWaitForever);
	osSemaphoreWait(xTIM7SemaphoreHandle,osWaitForever);

	HAL_TIM_PWM_Start(&htim13, TIM_CHANNEL_1);

	TIM6->DIER |= TIM_DIER_UIE; 				//разрешаем прерывание от таймера обновления структуры GUI_PID_STATE
	TIM6->EGR = TIM_EGR_UG;							//генерируем "update event". ARR и PSC грузятся из предварительного в теневой регистр.
	TIM6->SR&=~TIM_SR_UIF; 							//Сбрасываем флаг UIF
	NVIC_ClearPendingIRQ(TIM6_DAC_IRQn);

	TIM7->DIER |= TIM_DIER_UIE; 				//разрешаем прерывание от таймера обновления структуры GUI_PID_STATE
	TIM7->EGR = TIM_EGR_UG;							//генерируем "update event". ARR и PSC грузятся из предварительного в теневой регистр.
	TIM7->SR&=~TIM_SR_UIF; 							//Сбрасываем флаг UIF
	NVIC_ClearPendingIRQ(TIM7_IRQn);

  /* USER CODE END RTOS_THREADS */

  /* Create the queue(s) */
  /* definition and creation of QueuePrintLCD */
  osMessageQDef(QueuePrintLCD, 16, sizeof(LCDPrintTypeDef));
  QueuePrintLCDHandle = osMessageCreate(osMessageQ(QueuePrintLCD), NULL);

  /* definition and creation of QueueCANRecieve */
  //osMessageQDef(QueueCANRecieve, 10, sizeof(CANRX_TypeDef));
 // QueueCANRecieveHandle = osMessageCreate(osMessageQ(QueueCANRecieve), NULL);

  /* definition and creation of QueueCANTransmite */
 // osMessageQDef(QueueCANTransmite, 16, sizeof(CANTX_TypeDef));
 // QueueCANTransmiteHandle = osMessageCreate(osMessageQ(QueueCANTransmite), NULL);

  /* USER CODE BEGIN RTOS_QUEUES */
  /* add queues, ... */

		xQueueCANTX=xQueueCreate(4,sizeof(CANTX_TypeDef));
		xQueueCANRX=xQueueCreate(16,sizeof(CANRX_TypeDef));
  /* USER CODE END RTOS_QUEUES */

  /* Start scheduler */
  osKernelStart();

  /* We should never get here as control is now taken by the scheduler */

  /* Infinite loop */
  while (1)
  {

	}

}

/** System Clock Configuration
*/
void SystemClock_Config(void)
{

  RCC_OscInitTypeDef RCC_OscInitStruct;
  RCC_ClkInitTypeDef RCC_ClkInitStruct;
  RCC_PeriphCLKInitTypeDef PeriphClkInitStruct;

    /**Configure the main internal regulator output voltage
    */
  __HAL_RCC_PWR_CLK_ENABLE();

  __HAL_PWR_VOLTAGESCALING_CONFIG(PWR_REGULATOR_VOLTAGE_SCALE1);

    /**Initializes the CPU, AHB and APB busses clocks
    */
  RCC_OscInitStruct.OscillatorType = RCC_OSCILLATORTYPE_HSE|RCC_OSCILLATORTYPE_LSE;
  RCC_OscInitStruct.HSEState = RCC_HSE_ON;
  RCC_OscInitStruct.LSEState = RCC_LSE_ON;
  RCC_OscInitStruct.PLL.PLLState = RCC_PLL_ON;
  RCC_OscInitStruct.PLL.PLLSource = RCC_PLLSOURCE_HSE;
  RCC_OscInitStruct.PLL.PLLM = 8;
  RCC_OscInitStruct.PLL.PLLN = 360;
  RCC_OscInitStruct.PLL.PLLP = RCC_PLLP_DIV2;
  RCC_OscInitStruct.PLL.PLLQ = 8;
  if (HAL_RCC_OscConfig(&RCC_OscInitStruct) != HAL_OK)
  {
    _Error_Handler(__FILE__, __LINE__);
  }

    /**Activate the Over-Drive mode
    */
  if (HAL_PWREx_EnableOverDrive() != HAL_OK)
  {
    _Error_Handler(__FILE__, __LINE__);
  }

    /**Initializes the CPU, AHB and APB busses clocks
    */
  RCC_ClkInitStruct.ClockType = RCC_CLOCKTYPE_HCLK|RCC_CLOCKTYPE_SYSCLK
                              |RCC_CLOCKTYPE_PCLK1|RCC_CLOCKTYPE_PCLK2;
  RCC_ClkInitStruct.SYSCLKSource = RCC_SYSCLKSOURCE_PLLCLK;
  RCC_ClkInitStruct.AHBCLKDivider = RCC_SYSCLK_DIV1;
  RCC_ClkInitStruct.APB1CLKDivider = RCC_HCLK_DIV4;
  RCC_ClkInitStruct.APB2CLKDivider = RCC_HCLK_DIV2;

  if (HAL_RCC_ClockConfig(&RCC_ClkInitStruct, FLASH_LATENCY_5) != HAL_OK)
  {
    _Error_Handler(__FILE__, __LINE__);
  }

  PeriphClkInitStruct.PeriphClockSelection = RCC_PERIPHCLK_LTDC|RCC_PERIPHCLK_RTC;
  PeriphClkInitStruct.PLLSAI.PLLSAIN = 288;
  PeriphClkInitStruct.PLLSAI.PLLSAIR = 2;
  PeriphClkInitStruct.PLLSAIDivR = RCC_PLLSAIDIVR_16;
  PeriphClkInitStruct.RTCClockSelection = RCC_RTCCLKSOURCE_LSE;
  if (HAL_RCCEx_PeriphCLKConfig(&PeriphClkInitStruct) != HAL_OK)
  {
    _Error_Handler(__FILE__, __LINE__);
  }

    /**Configure the Systick interrupt time
    */
  HAL_SYSTICK_Config(HAL_RCC_GetHCLKFreq()/1000);

    /**Configure the Systick
    */
  HAL_SYSTICK_CLKSourceConfig(SYSTICK_CLKSOURCE_HCLK);

  /* SysTick_IRQn interrupt configuration */
  HAL_NVIC_SetPriority(SysTick_IRQn, 15, 0);
}

/* CRC init function */
static void MX_CRC_Init(void)
{

  hcrc.Instance = CRC;
  if (HAL_CRC_Init(&hcrc) != HAL_OK)
  {
    _Error_Handler(__FILE__, __LINE__);
  }

}

/* DMA2D init function */
static void MX_DMA2D_Init(void)
{

  hdma2d.Instance = DMA2D;
  hdma2d.Init.Mode = DMA2D_M2M_PFC;
  hdma2d.Init.ColorMode = DMA2D_OUTPUT_ARGB8888;
  hdma2d.Init.OutputOffset = 0;
  hdma2d.LayerCfg[1].InputOffset = 0;
  hdma2d.LayerCfg[1].InputColorMode = DMA2D_INPUT_A4;
  hdma2d.LayerCfg[1].AlphaMode = DMA2D_NO_MODIF_ALPHA;
  hdma2d.LayerCfg[1].InputAlpha = 0;
  if (HAL_DMA2D_Init(&hdma2d) != HAL_OK)
  {
    _Error_Handler(__FILE__, __LINE__);
  }

  if (HAL_DMA2D_ConfigLayer(&hdma2d, 1) != HAL_OK)
  {
    _Error_Handler(__FILE__, __LINE__);
  }

}

/* LTDC init function */
static void MX_LTDC_Init(void)
{

  LTDC_LayerCfgTypeDef pLayerCfg;
  LTDC_LayerCfgTypeDef pLayerCfg1;

  hltdc.Instance = LTDC;
  hltdc.Init.HSPolarity = LTDC_HSPOLARITY_AL;
  hltdc.Init.VSPolarity = LTDC_VSPOLARITY_AL;
  hltdc.Init.DEPolarity = LTDC_DEPOLARITY_AL;
  hltdc.Init.PCPolarity = LTDC_PCPOLARITY_IPC;
  hltdc.Init.HorizontalSync = 40;
  hltdc.Init.VerticalSync = 9;
  hltdc.Init.AccumulatedHBP = 42;
  hltdc.Init.AccumulatedVBP = 11;
  hltdc.Init.AccumulatedActiveW = 522;
  hltdc.Init.AccumulatedActiveH = 283;
  hltdc.Init.TotalWidth = 524;
  hltdc.Init.TotalHeigh = 285;
  hltdc.Init.Backcolor.Blue = 0;
  hltdc.Init.Backcolor.Green = 0;
  hltdc.Init.Backcolor.Red = 0;
  if (HAL_LTDC_Init(&hltdc) != HAL_OK)
  {
    _Error_Handler(__FILE__, __LINE__);
  }

  pLayerCfg.WindowX0 = 0;
  pLayerCfg.WindowX1 = 480;
  pLayerCfg.WindowY0 = 0;
  pLayerCfg.WindowY1 = 240;
  pLayerCfg.PixelFormat = LTDC_PIXEL_FORMAT_ARGB8888;
  pLayerCfg.Alpha = 255;
  pLayerCfg.Alpha0 = 0;
  pLayerCfg.BlendingFactor1 = LTDC_BLENDING_FACTOR1_PAxCA;
  pLayerCfg.BlendingFactor2 = LTDC_BLENDING_FACTOR2_PAxCA;
  pLayerCfg.FBStartAdress = 0xD0000000;
  pLayerCfg.ImageWidth = 480;
  pLayerCfg.ImageHeight = 240;
  pLayerCfg.Backcolor.Blue = 150;
  pLayerCfg.Backcolor.Green = 0;
  pLayerCfg.Backcolor.Red = 100;
  if (HAL_LTDC_ConfigLayer(&hltdc, &pLayerCfg, 0) != HAL_OK)
  {
    _Error_Handler(__FILE__, __LINE__);
  }

  pLayerCfg1.WindowX0 = 0;
  pLayerCfg1.WindowX1 = 480;
  pLayerCfg1.WindowY0 = 0;
  pLayerCfg1.WindowY1 = 272;
  pLayerCfg1.PixelFormat = LTDC_PIXEL_FORMAT_ARGB8888;
  pLayerCfg1.Alpha = 255;
  pLayerCfg1.Alpha0 = 0;
  pLayerCfg1.BlendingFactor1 = LTDC_BLENDING_FACTOR1_PAxCA;
  pLayerCfg1.BlendingFactor2 = LTDC_BLENDING_FACTOR2_PAxCA;
  pLayerCfg1.FBStartAdress = 0xD00ff000;
  pLayerCfg1.ImageWidth = 480;
  pLayerCfg1.ImageHeight = 272;
  pLayerCfg1.Backcolor.Blue = 150;
  pLayerCfg1.Backcolor.Green = 100;
  pLayerCfg1.Backcolor.Red = 0;
  if (HAL_LTDC_ConfigLayer(&hltdc, &pLayerCfg1, 1) != HAL_OK)
  {
    _Error_Handler(__FILE__, __LINE__);
  }

}

/* RTC init function */
static void MX_RTC_Init(void)
{

  RTC_TimeTypeDef sTime;
  RTC_DateTypeDef sDate;

    /**Initialize RTC Only
    */
  hrtc.Instance = RTC;
  hrtc.Init.HourFormat = RTC_HOURFORMAT_24;
  hrtc.Init.AsynchPrediv = 127;
  hrtc.Init.SynchPrediv = 255;
  hrtc.Init.OutPut = RTC_OUTPUT_DISABLE;
  hrtc.Init.OutPutPolarity = RTC_OUTPUT_POLARITY_HIGH;
  hrtc.Init.OutPutType = RTC_OUTPUT_TYPE_OPENDRAIN;
  if (HAL_RTC_Init(&hrtc) != HAL_OK)
  {
    _Error_Handler(__FILE__, __LINE__);
  }

    /**Initialize RTC and set the Time and Date
    */
  if(HAL_RTCEx_BKUPRead(&hrtc, RTC_BKP_DR0) != 0x32F2){
  sTime.Hours = 0x12;
  sTime.Minutes = 0x0;
  sTime.Seconds = 0x0;
  sTime.DayLightSaving = RTC_DAYLIGHTSAVING_NONE;
  sTime.StoreOperation = RTC_STOREOPERATION_RESET;
  if (HAL_RTC_SetTime(&hrtc, &sTime, RTC_FORMAT_BCD) != HAL_OK)
  {
    _Error_Handler(__FILE__, __LINE__);
  }

  sDate.WeekDay = RTC_WEEKDAY_FRIDAY;
  sDate.Month = RTC_MONTH_AUGUST;
  sDate.Date = 0x17;
  sDate.Year = 0x17;

  if (HAL_RTC_SetDate(&hrtc, &sDate, RTC_FORMAT_BCD) != HAL_OK)
  {
    _Error_Handler(__FILE__, __LINE__);
  }

    HAL_RTCEx_BKUPWrite(&hrtc,RTC_BKP_DR0,0x32F2);
  }
    /**Enable the WakeUp
    */
  __HAL_RTC_WAKEUPTIMER_CLEAR_FLAG(&hrtc, RTC_FLAG_WUTF);

  if (HAL_RTCEx_SetWakeUpTimer_IT(&hrtc, 0, RTC_WAKEUPCLOCK_CK_SPRE_16BITS) != HAL_OK)
  {
    _Error_Handler(__FILE__, __LINE__);
  }

}

/* TIM6 init function */
static void MX_TIM6_Init(void)
{

  TIM_MasterConfigTypeDef sMasterConfig;

  htim6.Instance = TIM6;
  htim6.Init.Prescaler = 44999;
  htim6.Init.CounterMode = TIM_COUNTERMODE_UP;
  htim6.Init.Period = 4000;
  if (HAL_TIM_Base_Init(&htim6) != HAL_OK)
  {
    _Error_Handler(__FILE__, __LINE__);
  }

  sMasterConfig.MasterOutputTrigger = TIM_TRGO_RESET;
  sMasterConfig.MasterSlaveMode = TIM_MASTERSLAVEMODE_DISABLE;
  if (HAL_TIMEx_MasterConfigSynchronization(&htim6, &sMasterConfig) != HAL_OK)
  {
    _Error_Handler(__FILE__, __LINE__);
  }

}

/* TIM7 init function */
static void MX_TIM7_Init(void)
{

  TIM_MasterConfigTypeDef sMasterConfig;

  htim7.Instance = TIM7;
  htim7.Init.Prescaler = 44999;
  htim7.Init.CounterMode = TIM_COUNTERMODE_UP;
  htim7.Init.Period = 2000;
  if (HAL_TIM_Base_Init(&htim7) != HAL_OK)
  {
    _Error_Handler(__FILE__, __LINE__);
  }

  sMasterConfig.MasterOutputTrigger = TIM_TRGO_RESET;
  sMasterConfig.MasterSlaveMode = TIM_MASTERSLAVEMODE_DISABLE;
  if (HAL_TIMEx_MasterConfigSynchronization(&htim7, &sMasterConfig) != HAL_OK)
  {
    _Error_Handler(__FILE__, __LINE__);
  }

}

/* TIM13 init function */
static void MX_TIM13_Init(void)
{

  TIM_OC_InitTypeDef sConfigOC;

  htim13.Instance = TIM13;
  htim13.Init.Prescaler = 4499;
  htim13.Init.CounterMode = TIM_COUNTERMODE_UP;
  htim13.Init.Period = 200;
  htim13.Init.ClockDivision = TIM_CLOCKDIVISION_DIV1;
  if (HAL_TIM_Base_Init(&htim13) != HAL_OK)
  {
    _Error_Handler(__FILE__, __LINE__);
  }

  if (HAL_TIM_PWM_Init(&htim13) != HAL_OK)
  {
    _Error_Handler(__FILE__, __LINE__);
  }

  sConfigOC.OCMode = TIM_OCMODE_PWM2;
  sConfigOC.Pulse = 70;
  sConfigOC.OCPolarity = TIM_OCPOLARITY_LOW;
  sConfigOC.OCFastMode = TIM_OCFAST_DISABLE;
  if (HAL_TIM_PWM_ConfigChannel(&htim13, &sConfigOC, TIM_CHANNEL_1) != HAL_OK)
  {
    _Error_Handler(__FILE__, __LINE__);
  }

  HAL_TIM_MspPostInit(&htim13);

}

/* USART1 init function */
static void MX_USART1_UART_Init(void)
{

  huart1.Instance = USART1;
  huart1.Init.BaudRate = 115200;
  huart1.Init.WordLength = UART_WORDLENGTH_8B;
  huart1.Init.StopBits = UART_STOPBITS_1;
  huart1.Init.Parity = UART_PARITY_NONE;
  huart1.Init.Mode = UART_MODE_TX_RX;
  huart1.Init.HwFlowCtl = UART_HWCONTROL_NONE;
  huart1.Init.OverSampling = UART_OVERSAMPLING_16;
  if (HAL_UART_Init(&huart1) != HAL_OK)
  {
    _Error_Handler(__FILE__, __LINE__);
  }

}

static void MX_DMA_Init(void)
{
  /* DMA controller clock enable */
  __HAL_RCC_DMA2_CLK_ENABLE();

  /* DMA interrupt init */
  /* DMA2_Stream2_IRQn interrupt configuration */
  HAL_NVIC_SetPriority(DMA2_Stream2_IRQn, 5, 0);
  HAL_NVIC_EnableIRQ(DMA2_Stream2_IRQn);
  /* DMA2_Stream7_IRQn interrupt configuration */
  HAL_NVIC_SetPriority(DMA2_Stream7_IRQn, 5, 0);
  HAL_NVIC_EnableIRQ(DMA2_Stream7_IRQn);

}
/* FMC initialization function */
static void MX_FMC_Init(void)
{
  FMC_SDRAM_TimingTypeDef SdramTiming;

  /** Perform the SDRAM2 memory initialization sequence
  */
  hsdram2.Instance = FMC_SDRAM_DEVICE;
  /* hsdram2.Init */
  hsdram2.Init.SDBank = FMC_SDRAM_BANK2;
  hsdram2.Init.ColumnBitsNumber = FMC_SDRAM_COLUMN_BITS_NUM_8;
  hsdram2.Init.RowBitsNumber = FMC_SDRAM_ROW_BITS_NUM_12;
  hsdram2.Init.MemoryDataWidth = FMC_SDRAM_MEM_BUS_WIDTH_16;
  hsdram2.Init.InternalBankNumber = FMC_SDRAM_INTERN_BANKS_NUM_4;
  hsdram2.Init.CASLatency = FMC_SDRAM_CAS_LATENCY_3;
  hsdram2.Init.WriteProtection = FMC_SDRAM_WRITE_PROTECTION_DISABLE;
  hsdram2.Init.SDClockPeriod = FMC_SDRAM_CLOCK_PERIOD_2;
  hsdram2.Init.ReadBurst = FMC_SDRAM_RBURST_ENABLE;
  hsdram2.Init.ReadPipeDelay = FMC_SDRAM_RPIPE_DELAY_2;
  /* SdramTiming */
  SdramTiming.LoadToActiveDelay = 2;
  SdramTiming.ExitSelfRefreshDelay = 7;
  SdramTiming.SelfRefreshTime = 4;
  SdramTiming.RowCycleDelay = 6;
  SdramTiming.WriteRecoveryTime = 2;
  SdramTiming.RPDelay = 2;
  SdramTiming.RCDDelay = 2;

  if (HAL_SDRAM_Init(&hsdram2, &SdramTiming) != HAL_OK)
  {
    _Error_Handler(__FILE__, __LINE__);
  }

}

/** Configure pins as
        * Analog
        * Input
        * Output
        * EVENT_OUT
        * EXTI
*/
static void MX_GPIO_Init(void)
{

  GPIO_InitTypeDef GPIO_InitStruct;

  /* GPIO Ports Clock Enable */
  __HAL_RCC_GPIOE_CLK_ENABLE();
  __HAL_RCC_GPIOC_CLK_ENABLE();
  __HAL_RCC_GPIOI_CLK_ENABLE();
  __HAL_RCC_GPIOF_CLK_ENABLE();
  __HAL_RCC_GPIOH_CLK_ENABLE();
  __HAL_RCC_GPIOA_CLK_ENABLE();
  __HAL_RCC_GPIOG_CLK_ENABLE();
  __HAL_RCC_GPIOD_CLK_ENABLE();
  __HAL_RCC_GPIOB_CLK_ENABLE();

  /*Configure GPIO pin Output Level */
  HAL_GPIO_WritePin(GPIOF, Led1_Pin|Led2_Pin|Led3_Pin|Led4_Pin, GPIO_PIN_RESET);

  /*Configure GPIO pins : Led1_Pin Led2_Pin Led3_Pin Led4_Pin */
  GPIO_InitStruct.Pin = Led1_Pin|Led2_Pin|Led3_Pin|Led4_Pin;
  GPIO_InitStruct.Mode = GPIO_MODE_OUTPUT_PP;
  GPIO_InitStruct.Pull = GPIO_NOPULL;
  GPIO_InitStruct.Speed = GPIO_SPEED_FREQ_LOW;
  HAL_GPIO_Init(GPIOF, &GPIO_InitStruct);

  /*Configure GPIO pins : Joystick_A_Pin Joystick_B_Pin Joystick_C_Pin Joystick_D_Pin */
  GPIO_InitStruct.Pin = Joystick_A_Pin|Joystick_B_Pin|Joystick_C_Pin|Joystick_D_Pin;
  GPIO_InitStruct.Mode = GPIO_MODE_IT_FALLING;
  GPIO_InitStruct.Pull = GPIO_PULLUP;
  HAL_GPIO_Init(GPIOG, &GPIO_InitStruct);

  /* EXTI interrupt init*/
  HAL_NVIC_SetPriority(EXTI2_IRQn, 10, 0);
  HAL_NVIC_EnableIRQ(EXTI2_IRQn);

  HAL_NVIC_SetPriority(EXTI3_IRQn, 10, 0);
  HAL_NVIC_EnableIRQ(EXTI3_IRQn);

  HAL_NVIC_SetPriority(EXTI9_5_IRQn, 10, 0);
  HAL_NVIC_EnableIRQ(EXTI9_5_IRQn);

  HAL_NVIC_SetPriority(EXTI15_10_IRQn, 10, 0);
  HAL_NVIC_EnableIRQ(EXTI15_10_IRQn);

}

/* USER CODE BEGIN 4 */

void SDRAM_Initialization_sequence(uint32_t RefreshCount)
{
	uint32_t tmp;

#define SDRAM_MODEREG_BURST_LENGTH_1             ((uint16_t)0x0000)
	#define SDRAM_MODEREG_BURST_LENGTH_2             ((uint16_t)0x0001)
	#define SDRAM_MODEREG_BURST_LENGTH_4             ((uint16_t)0x0002)
	#define SDRAM_MODEREG_BURST_LENGTH_8             ((uint16_t)0x0004)
	#define SDRAM_MODEREG_BURST_TYPE_SEQUENTIAL      ((uint16_t)0x0000)
	#define SDRAM_MODEREG_BURST_TYPE_INTERLEAVED     ((uint16_t)0x0008)
	#define SDRAM_MODEREG_CAS_LATENCY_2              ((uint16_t)0x0020)
	#define SDRAM_MODEREG_CAS_LATENCY_3              ((uint16_t)0x0030)
	#define SDRAM_MODEREG_OPERATING_MODE_STANDARD    ((uint16_t)0x0000)
	#define SDRAM_MODEREG_WRITEBURST_MODE_PROGRAMMED ((uint16_t)0x0000)
	#define SDRAM_MODEREG_WRITEBURST_MODE_SINGLE     ((uint16_t)0x0200)

	FMC_SDRAM_CommandTypeDef Command;

	__IO uint32_t tmpmrd =0;

  /* Step 1:  Configure a clock configuration enable command */
  Command.CommandMode             = FMC_SDRAM_CMD_CLK_ENABLE;
  Command.CommandTarget           = FMC_SDRAM_CMD_TARGET_BANK2;
  Command.AutoRefreshNumber       = 1;
  Command.ModeRegisterDefinition  = 0;

  /* Send the command */
  HAL_SDRAM_SendCommand(&hsdram2, &Command, SDRAM_TIMEOUT);

  /* Step 2: Insert 100 us minimum delay */
  /* Inserted delay is equal to 1 ms due to systick time base unit (ms) */
  HAL_Delay(1);

  /* Step 3: Configure a PALL (precharge all) command */
  Command.CommandMode             = FMC_SDRAM_CMD_PALL;
  Command.CommandTarget           = FMC_SDRAM_CMD_TARGET_BANK2;
  Command.AutoRefreshNumber       = 1;
  Command.ModeRegisterDefinition  = 0;

  /* Send the command */
  HAL_SDRAM_SendCommand(&hsdram2, &Command, SDRAM_TIMEOUT);

  /* Step 4: Configure an Auto Refresh command */
  Command.CommandMode             = FMC_SDRAM_CMD_AUTOREFRESH_MODE;
  Command.CommandTarget           = FMC_SDRAM_CMD_TARGET_BANK2;
  Command.AutoRefreshNumber       = 4;
  Command.ModeRegisterDefinition  = 0;

  /* Send the command */
  HAL_SDRAM_SendCommand(&hsdram2, &Command, SDRAM_TIMEOUT);

  /* Step 5: Program the external memory mode register */
  tmpmrd = (uint32_t)SDRAM_MODEREG_BURST_LENGTH_2          |
                     SDRAM_MODEREG_BURST_TYPE_SEQUENTIAL   |
                     SDRAM_MODEREG_CAS_LATENCY_3           |
                     SDRAM_MODEREG_OPERATING_MODE_STANDARD |
                     SDRAM_MODEREG_WRITEBURST_MODE_SINGLE;

  Command.CommandMode             = FMC_SDRAM_CMD_LOAD_MODE;
  Command.CommandTarget           = FMC_SDRAM_CMD_TARGET_BANK2;
  Command.AutoRefreshNumber       = 1;
  Command.ModeRegisterDefinition  = tmpmrd;

  /* Send the command */
  HAL_SDRAM_SendCommand(&hsdram2, &Command, SDRAM_TIMEOUT);

  /* Step 6: Set the refresh rate counter */
  /* Set the device refresh rate */
  HAL_SDRAM_ProgramRefreshRate(&hsdram2, RefreshCount);

// Clear SDRAM
	while(FMC_Bank5_6->SDSR&FMC_SDSR_BUSY);
	for(tmpmrd=SDRAM_BASE;tmpmrd<(SDRAM_BASE+SDRAM_SIZE);tmpmrd+=4)
	*(uint32_t*)tmpmrd=0x0;

#if 0
// Initialization step 3
		FMC_Bank5_6->SDCMR=FMC_SDCMR_MODE_0|								// 001 Clock Configuration Enable
											 FMC_SDCMR_CTB2  |								// Command issued to SDRAM Bank 2
											 FMC_SDCMR_NRFS_0;								// 2 Auto-refresh cycles
// Initialization step 4
		/* Delay 100 mS*/
		for(tmp = 0; tmp < 1000000; tmp++);
// Initialization step 5
	while(FMC_Bank5_6->SDSR&FMC_SDSR_BUSY);
	FMC_Bank5_6->SDCMR=FMC_SDCMR_MODE_1|									// 010 PALL (“All Bank Precharge”) command
										 FMC_SDCMR_CTB2	 |									// Command issued to SDRAM Bank 2
										 FMC_SDCMR_NRFS_0;									// 2 Auto-refresh cycles
// Initialization step 6
	while(FMC_Bank5_6->SDSR&FMC_SDSR_BUSY);
	FMC_Bank5_6->SDCMR=  FMC_SDCMR_MODE_2|								// 011: Auto-refresh command
										   FMC_SDCMR_CTB2|									// Command issued to SDRAM Bank 2
	FMC_SDCMR_NRFS_0|FMC_SDCMR_NRFS_1|FMC_SDCMR_NRFS_2;		// Number of Auto-refresh 8 cycle (0111)
// Initialization step 7
 #define SDRAM_BURST_LENGTH_1                ((uint16_t)0x0000)
 #define SDRAM_BURST_LENGTH_2                ((uint16_t)0x0001)
 #define SDRAM_BURST_LENGTH_4                ((uint16_t)0x0002)
 #define SDRAM_BURST_LENGTH_8                ((uint16_t)0x0004)
 #define SDRAM_BURST_TYPE_SEQUENTIAL         ((uint16_t)0x0000)
 #define SDRAM_BURST_TYPE_INTERLEAVED        ((uint16_t)0x0008)
 #define SDRAM_CAS_LATENCY_2                 ((uint16_t)0x0020)
 #define SDRAM_CAS_LATENCY_3                 ((uint16_t)0x0030)
 #define SDRAM_OPERATING_MODE_STANDARD       ((uint16_t)0x0000)
 #define SDRAM_WRITEBURST_MODE_PROGRAMMED    ((uint16_t)0x0000)
 #define SDRAM_WRITEBURST_MODE_SINGLE        ((uint16_t)0x0200)
 #define FMC_SDCMR_MODE_3										 ((uint32_t)0x00000004)
	while(FMC_Bank5_6->SDSR&FMC_SDSR_BUSY);
	FMC_Bank5_6->SDCMR=FMC_SDCMR_MODE_3|									// Command mode 100: Load Mode Register
											FMC_SDCMR_CTB2 |									//   Command issued to SDRAM Bank 2
											FMC_SDCMR_NRFS_0|							  	// 2 Auto-refresh cycles
											SDRAM_BURST_LENGTH_2<<9|
											SDRAM_BURST_TYPE_SEQUENTIAL<<9|
											SDRAM_CAS_LATENCY_3<<9|
											SDRAM_OPERATING_MODE_STANDARD<<9|
											SDRAM_WRITEBURST_MODE_SINGLE<<9;
// Initialization step 8
	while(FMC_Bank5_6->SDSR&FMC_SDSR_BUSY);
	FMC_Bank5_6->SDRTR|=(1386<<1);													// 64mS/4096=15.625uS
																													// 15.625*90MHz-20=1386
	// Clear SDRAM
	while(FMC_Bank5_6->SDSR&FMC_SDSR_BUSY);
	for(tmp=SDRAM_BASE;tmp<(SDRAM_BASE+SDRAM_SIZE);tmp+=4)
	*(uint32_t*)tmp=0x0;
#endif

}
/* USER CODE END 4 */

/* StartDefaultTask function */
void StartDefaultTask(void const * argument)
{

  /* USER CODE BEGIN 5 */

  /* Infinite loop */
  for(;;)
  {
   	LCD_PutString("EN",LCD_XSIZE-390,2,1,MAGENTA,0xFF);
		LCD_PutString("Load",LCD_XSIZE-357,2,1,GREEN,0xFF);
		LCD_PutString("Heap",LCD_XSIZE-100,26,1,GREEN,0xFF);

		LCD_ClearRec(0,0,LCD_XSIZE,2,LAYER_1,YELLOW,180);
		LCD_ClearRec(2,24,LCD_XSIZE-4,2,LAYER_1,YELLOW,180);
		LCD_ClearRec(2,240,LCD_XSIZE-4,2,LAYER_1,YELLOW,180);
		LCD_ClearRec(0,270,LCD_XSIZE,2,LAYER_1,YELLOW,180);

		LCD_ClearRec(LCD_XSIZE-395,2,2,22,LAYER_1,YELLOW,180);
		LCD_ClearRec(LCD_XSIZE-365,2,2,22,LAYER_1,YELLOW,180);
		LCD_ClearRec(LCD_XSIZE-200,2,2,22,LAYER_1,YELLOW,180);
		LCD_ClearRec(LCD_XSIZE-90,2,2,22,LAYER_1,YELLOW,180);

		LCD_ClearRec(0,0,2,LCD_YSIZE,LAYER_1,YELLOW,180);
		LCD_ClearRec(LCD_XSIZE-2,0,2,LCD_YSIZE,LAYER_1,YELLOW,180);

		//LCD_PutString("*****************************************************", LCD_XSIZE-479,228,1,GREEN,0xFF);
		PS2_KBD_LowLevelInit();
		if(PS2_KBD_Tx(0xFF)!=SUCCESS)
			PS2_KBD_LowLevelDeInit();

		bxCAN_Init();

		osDelay(1000);

		osThreadResume (LCDPrintCurrentHandle);
		osThreadResume (PrintKernelLoadHandle);
		osThreadResume (PrintRTCHandle);
		osThreadResume(LED1BlinkHandle);
		osThreadResume(LED2BlinkHandle);
		osThreadResume(LED3BlinkHandle);
		osThreadResume(LED4BlinkHandle);
		osThreadResume(CommandMsgDecodHandle);
		osThreadResume(LCDBlinkCursorHandle);
		osThreadResume(PS2CharDecodeHandle);
		osThreadTerminate (defaultTaskHandle);
  }
  /* USER CODE END 5 */
}

void HAL_TIM_PeriodElapsedCallback(TIM_HandleTypeDef *htim)
{
  if (htim->Instance == TIM14) {
    HAL_IncTick();
  }
}

void _Error_Handler(char * file, int line)
{
  while(1)
  {
  }
}

/************************ (C) COPYRIGHT STMicroelectronics *****END OF FILE****/

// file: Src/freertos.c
/**
  ******************************************************************************
  * File Name          : freertos.c
  * Description        : Code for freertos applications
  ******************************************************************************
  * This notice applies to any and all portions of this file
  * that are not between comment pairs USER CODE BEGIN and
  * USER CODE END. Other portions of this file, whether
  * inserted by the user or by software development tools
  * are owned by their respective copyright owners.
  *
  * Copyright (c) 2017 STMicroelectronics International N.V.
  * All rights reserved.
  *
  * Redistribution and use in source and binary forms, with or without
  * modification, are permitted, provided that the following conditions are met:
  *
  * 1. Redistribution of source code must retain the above copyright notice,
  *    this list of conditions and the following disclaimer.
  * 2. Redistributions in binary form must reproduce the above copyright notice,
  *    this list of conditions and the following disclaimer in the documentation
  *    and/or other materials provided with the distribution.
  * 3. Neither the name of STMicroelectronics nor the names of other
  *    contributors to this software may be used to endorse or promote products
  *    derived from this software without specific written permission.
  * 4. This software, including modifications and/or derivative works of this
  *    software, must execute solely and exclusively on microcontroller or
  *    microprocessor devices manufactured by or for STMicroelectronics.
  * 5. Redistribution and use of this software other than as permitted under
  *    this license is void and will automatically terminate your rights under
  *    this license.
  *
  * THIS SOFTWARE IS PROVIDED BY STMICROELECTRONICS AND CONTRIBUTORS "AS IS"
  * AND ANY EXPRESS, IMPLIED OR STATUTORY WARRANTIES, INCLUDING, BUT NOT
  * LIMITED TO, THE IMPLIED WARRANTIES OF MERCHANTABILITY, FITNESS FOR A
  * PARTICULAR PURPOSE AND NON-INFRINGEMENT OF THIRD PARTY INTELLECTUAL PROPERTY
  * RIGHTS ARE DISCLAIMED TO THE FULLEST EXTENT PERMITTED BY LAW. IN NO EVENT
  * SHALL STMICROELECTRONICS OR CONTRIBUTORS BE LIABLE FOR ANY DIRECT, INDIRECT,
  * INCIDENTAL, SPECIAL, EXEMPLARY, OR CONSEQUENTIAL DAMAGES (INCLUDING, BUT NOT
  * LIMITED TO, PROCUREMENT OF SUBSTITUTE GOODS OR SERVICES; LOSS OF USE, DATA,
  * OR PROFITS; OR BUSINESS INTERRUPTION) HOWEVER CAUSED AND ON ANY THEORY OF
  * LIABILITY, WHETHER IN CONTRACT, STRICT LIABILITY, OR TORT (INCLUDING
  * NEGLIGENCE OR OTHERWISE) ARISING IN ANY WAY OUT OF THE USE OF THIS SOFTWARE,
  * EVEN IF ADVISED OF THE POSSIBILITY OF SUCH DAMAGE.
  *
  ******************************************************************************
  */

#include "FreeRTOS.h"
#include "task.h"

/* Hook prototypes */
void vApplicationIdleHook(void);

/* USER CODE BEGIN 2 */
__weak void vApplicationIdleHook( void )
{
   /* vApplicationIdleHook() will only be called if configUSE_IDLE_HOOK is set
   to 1 in FreeRTOSConfig.h. It will be called on each iteration of the idle
   task. It is essential that code added to this hook function never attempts
   to block in any way (for example, call xQueueReceive() with a block time
   specified, or call vTaskDelay()). If the application makes use of the
   vTaskDelete() API function (as this demo application does) then it is also
   important that vApplicationIdleHook() is permitted to return to its calling
   function, because it is the responsibility of the idle task to clean up
   memory allocated by the kernel to any task that has since been deleted. */
}
/* USER CODE END 2 */

/************************ (C) COPYRIGHT STMicroelectronics *****END OF FILE****/
